# RX64M_QSPI_Pilot register map
File version: 1.0
RX64M_QSPI_Pilot peripheral registers generated from iodefine.h (pilot).
Registers are 8-bit, read-write, reset 0x0 unless marked. A register's access mark holds for its fields unless they carry their own. Offsets are from the block's base; lines under a group give offsets from that group; [hi:lo] are bit positions; {n}, {i} and the like mark numbered series; 'fields as' and 'values as' point back to an identical list; <NAME> marks a mode.

## Memory map
0x00089E00 QSPI size 0x2C

## QSPI
Base 0x00089E00
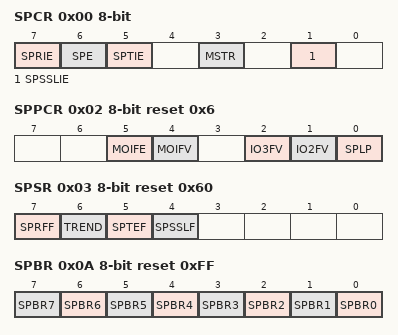
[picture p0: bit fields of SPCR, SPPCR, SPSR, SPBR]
0x00 SPCR
  [7] SPRIE, [6] SPE, [5] SPTIE, [3] MSTR, [1] SPSSLIE
0x01 SSLP
  [0] SSLP
0x02 SPPCR reset 0x6
  [5] MOIFE, [4] MOIFV, [2] IO3FV, [1] IO2FV, [0] SPLP
0x03 SPSR reset 0x60
  [7] SPRFF, [6] TREND, [5] SPTEF, [4] SPSSLF
0x04 SPDR 32-bit reset not defined
0x08 SPSCR
  [1:0] SPSC
0x09 SPSSR
  [1:0] SPSS
0x0A SPBR reset 0xFF
  [n] SPBR{n} (n=0..7)
0x0B SPDCR
  [7] TXDMY
0x0C SPCKD
  [2:0] SCKDL
0x0D SSLND
  [2:0] SLNDL
0x0E SPND
  [2:0] SPNDL
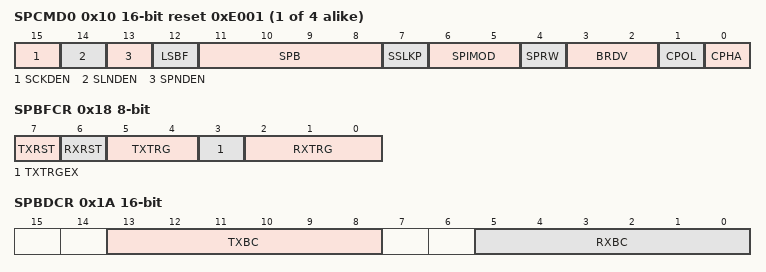
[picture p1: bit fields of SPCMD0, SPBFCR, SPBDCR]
{0x10+2i} SPCMD{i} 16-bit reset 0xE001 (i=0..3)
  [15] SCKDEN, [14] SLNDEN, [13] SPNDEN, [12] LSBF, [11:8] SPB, [7] SSLKP, [6:5] SPIMOD, [4] SPRW, [3:2] BRDV, [1] CPOL, [0] CPHA
0x18 SPBFCR
  [7] TXRST, [6] RXRST, [5:4] TXTRG, [3] TXTRGEX, [2:0] RXTRG
0x1A SPBDCR 16-bit
  [13:8] TXBC, [5:0] RXBC
{0x1C+4i} SPBMUL{i} 32-bit reset 0x1 (i=0..3)
